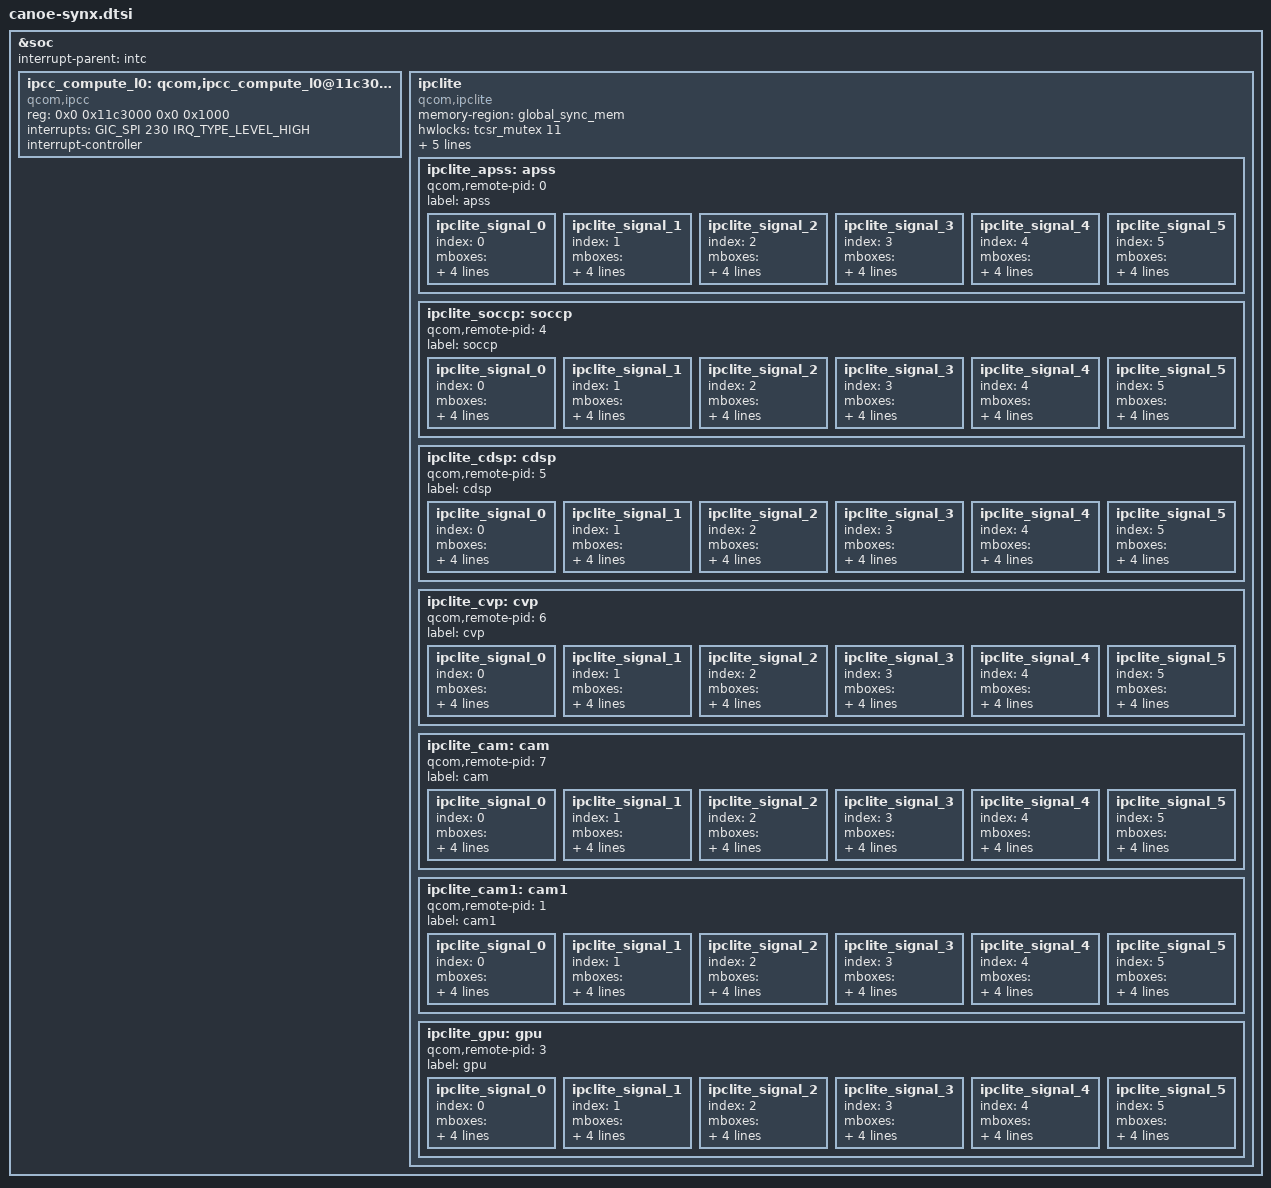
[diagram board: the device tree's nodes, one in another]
/* Copyright (c) Qualcomm Technologies, Inc. and/or its subsidiaries.
 * SPDX-License-Identifier: BSD-3-Clause
 */
#include <dt-bindings/ipclite-signals.h>

&soc {
	#address-cells = <2>;
	#size-cells = <2>;
	interrupt-parent = <&intc>;

	ipcc_compute_l0: qcom,ipcc_compute_l0@11c3000 {
		compatible = "qcom,ipcc";
		reg = <0x0 0x11c3000 0x0 0x1000>;
		interrupts = <GIC_SPI 230 IRQ_TYPE_LEVEL_HIGH>;
		interrupt-controller;
		#interrupt-cells = <3>;
		#mbox-cells = <2>;
	};
	ipclite {
		compatible = "qcom,ipclite";
		memory-region = <&global_sync_mem>;
		hwlocks = <&tcsr_mutex 11>;
		#address-cells = <2>;
		#size-cells = <2>;
		major_version = <1>;
		minor_version = <0>;
		feature_mask_low = <0x000F>;
		feature_mask_high = <0x0000>;
		global_par_custom_val=<40>;
		ranges;

		ipclite_apss: apss {
			qcom,remote-pid = <0>;
			label = "apss";

			ipclite_signal_0 {
				index = <0>;
				mboxes = <&ipcc_compute_l0 IPCC_COMPUTE_L0_APSS
					IPCC_COMPUTE_L0_SIGNAL_IPCLITE_MSG>;
					interrupt-parent = <&ipcc_compute_l0>;
				interrupts = <IPCC_COMPUTE_L0_APSS
					IPCC_COMPUTE_L0_SIGNAL_IPCLITE_MSG
					IRQ_TYPE_EDGE_RISING>;
			};

			ipclite_signal_1 {
				index = <1>;
				mboxes = <&ipcc_compute_l0 IPCC_CLIENT_BROADCAST
					IPCC_COMPUTE_L0_SIGNAL_IPCLITE_MEM_INIT>;
				interrupt-parent = <&ipcc_compute_l0>;
				interrupts = <IPCC_CLIENT_BROADCAST
					IPCC_COMPUTE_L0_SIGNAL_IPCLITE_MEM_INIT
					IRQ_TYPE_EDGE_RISING>;
			};

			ipclite_signal_2 {
				index = <2>;
				mboxes = <&ipcc_compute_l0 IPCC_COMPUTE_L0_APSS
					IPCC_COMPUTE_L0_SIGNAL_IPCLITE_VERSION>;
				interrupt-parent = <&ipcc_compute_l0>;
				interrupts = <IPCC_COMPUTE_L0_APSS
					IPCC_COMPUTE_L0_SIGNAL_IPCLITE_VERSION
					IRQ_TYPE_EDGE_RISING>;
			};

			ipclite_signal_3 {
				index = <3>;
				mboxes = <&ipcc_compute_l0 IPCC_COMPUTE_L0_APSS
					IPCC_COMPUTE_L0_SIGNAL_IPCLITE_TEST>;
				interrupt-parent = <&ipcc_compute_l0>;
				interrupts = <IPCC_COMPUTE_L0_APSS
					IPCC_COMPUTE_L0_SIGNAL_IPCLITE_TEST
					IRQ_TYPE_EDGE_RISING>;
			};

			ipclite_signal_4 {
				index = <4>;
				mboxes = <&ipcc_compute_l0 IPCC_COMPUTE_L0_APSS
					IPCC_COMPUTE_L0_SIGNAL_IPCLITE_SSR>;
				interrupt-parent = <&ipcc_compute_l0>;
				interrupts = <IPCC_COMPUTE_L0_APSS
					IPCC_COMPUTE_L0_SIGNAL_IPCLITE_SSR
					IRQ_TYPE_EDGE_RISING>;
			};

			ipclite_signal_5 {
				index = <5>;
				mboxes = <&ipcc_compute_l0 IPCC_COMPUTE_L0_APSS
					IPCC_COMPUTE_L0_SIGNAL_IPCLITE_DEBUG>;
				interrupt-parent = <&ipcc_compute_l0>;
				interrupts = <IPCC_COMPUTE_L0_APSS
					IPCC_COMPUTE_L0_SIGNAL_IPCLITE_DEBUG
					IRQ_TYPE_EDGE_RISING>;
			};
		};

		ipclite_soccp: soccp {
			qcom,remote-pid = <4>;
			label = "soccp";

			ipclite_signal_0 {
				index = <0>;
				mboxes = <&ipcc_compute_l0 IPCC_COMPUTE_L0_SOCCP
					IPCC_COMPUTE_L0_SIGNAL_IPCLITE_MSG>;
				interrupt-parent = <&ipcc_compute_l0>;
				interrupts = <IPCC_COMPUTE_L0_SOCCP
					IPCC_COMPUTE_L0_SIGNAL_IPCLITE_MSG
					IRQ_TYPE_EDGE_RISING>;
			};

			ipclite_signal_1 {
				index = <1>;
				mboxes = <&ipcc_compute_l0 IPCC_COMPUTE_L0_SOCCP
					IPCC_COMPUTE_L0_SIGNAL_IPCLITE_MEM_INIT>;
				interrupt-parent = <&ipcc_compute_l0>;
				interrupts = <IPCC_COMPUTE_L0_SOCCP
					IPCC_COMPUTE_L0_SIGNAL_IPCLITE_MEM_INIT
					IRQ_TYPE_EDGE_RISING>;
			};

			ipclite_signal_2 {
				index = <2>;
				mboxes = <&ipcc_compute_l0 IPCC_COMPUTE_L0_SOCCP
					IPCC_COMPUTE_L0_SIGNAL_IPCLITE_VERSION>;
				interrupt-parent = <&ipcc_compute_l0>;
				interrupts = <IPCC_COMPUTE_L0_SOCCP
					IPCC_COMPUTE_L0_SIGNAL_IPCLITE_VERSION
					IRQ_TYPE_EDGE_RISING>;
			};

			ipclite_signal_3 {
				index = <3>;
				mboxes = <&ipcc_compute_l0 IPCC_COMPUTE_L0_SOCCP
					IPCC_COMPUTE_L0_SIGNAL_IPCLITE_TEST>;
				interrupt-parent = <&ipcc_compute_l0>;
				interrupts = <IPCC_COMPUTE_L0_SOCCP
					IPCC_COMPUTE_L0_SIGNAL_IPCLITE_TEST
					IRQ_TYPE_EDGE_RISING>;
			};

			ipclite_signal_4 {
				index = <4>;
				mboxes = <&ipcc_compute_l0 IPCC_COMPUTE_L0_SOCCP
					IPCC_COMPUTE_L0_SIGNAL_IPCLITE_SSR>;
				interrupt-parent = <&ipcc_compute_l0>;
				interrupts = <IPCC_COMPUTE_L0_SOCCP
					IPCC_COMPUTE_L0_SIGNAL_IPCLITE_SSR
					IRQ_TYPE_EDGE_RISING>;
			};

			ipclite_signal_5 {
				index = <5>;
				mboxes = <&ipcc_compute_l0 IPCC_COMPUTE_L0_SOCCP
					IPCC_COMPUTE_L0_SIGNAL_IPCLITE_DEBUG>;
				interrupt-parent = <&ipcc_compute_l0>;
				interrupts = <IPCC_COMPUTE_L0_SOCCP
					IPCC_COMPUTE_L0_SIGNAL_IPCLITE_DEBUG
					IRQ_TYPE_EDGE_RISING>;
			};
		};

		ipclite_cdsp: cdsp {
			qcom,remote-pid = <5>;
			label = "cdsp";

			ipclite_signal_0 {
				index = <0>;
				mboxes = <&ipcc_compute_l0 IPCC_COMPUTE_L0_CDSP
					IPCC_COMPUTE_L0_SIGNAL_IPCLITE_MSG>;
				interrupt-parent = <&ipcc_compute_l0>;
				interrupts = <IPCC_COMPUTE_L0_CDSP
					IPCC_COMPUTE_L0_SIGNAL_IPCLITE_MSG
					IRQ_TYPE_EDGE_RISING>;
			};

			ipclite_signal_1 {
				index = <1>;
				mboxes = <&ipcc_compute_l0 IPCC_COMPUTE_L0_CDSP
					IPCC_COMPUTE_L0_SIGNAL_IPCLITE_MEM_INIT>;
				interrupt-parent = <&ipcc_compute_l0>;
				interrupts = <IPCC_COMPUTE_L0_CDSP
					IPCC_COMPUTE_L0_SIGNAL_IPCLITE_MEM_INIT
					IRQ_TYPE_EDGE_RISING>;
			};

			ipclite_signal_2 {
				index = <2>;
				mboxes = <&ipcc_compute_l0 IPCC_COMPUTE_L0_CDSP
					IPCC_COMPUTE_L0_SIGNAL_IPCLITE_VERSION>;
				interrupt-parent = <&ipcc_compute_l0>;
				interrupts = <IPCC_COMPUTE_L0_CDSP
					IPCC_COMPUTE_L0_SIGNAL_IPCLITE_VERSION
					IRQ_TYPE_EDGE_RISING>;
			};

			ipclite_signal_3 {
				index = <3>;
				mboxes = <&ipcc_compute_l0 IPCC_COMPUTE_L0_CDSP
					IPCC_COMPUTE_L0_SIGNAL_IPCLITE_TEST>;
				interrupt-parent = <&ipcc_compute_l0>;
				interrupts = <IPCC_COMPUTE_L0_CDSP
					IPCC_COMPUTE_L0_SIGNAL_IPCLITE_TEST
					IRQ_TYPE_EDGE_RISING>;
			};

			ipclite_signal_4 {
				index = <4>;
				mboxes = <&ipcc_compute_l0 IPCC_COMPUTE_L0_CDSP
					IPCC_COMPUTE_L0_SIGNAL_IPCLITE_SSR>;
				interrupt-parent = <&ipcc_compute_l0>;
				interrupts = <IPCC_COMPUTE_L0_CDSP
					IPCC_COMPUTE_L0_SIGNAL_IPCLITE_SSR
					IRQ_TYPE_EDGE_RISING>;
			};

			ipclite_signal_5 {
				index = <5>;
				mboxes = <&ipcc_compute_l0 IPCC_COMPUTE_L0_CDSP
					IPCC_COMPUTE_L0_SIGNAL_IPCLITE_DEBUG>;
				interrupt-parent = <&ipcc_compute_l0>;
				interrupts = <IPCC_COMPUTE_L0_CDSP
					IPCC_COMPUTE_L0_SIGNAL_IPCLITE_DEBUG
					IRQ_TYPE_EDGE_RISING>;
			};
		};

		ipclite_cvp: cvp {
			qcom,remote-pid = <6>;
			label = "cvp";

			ipclite_signal_0 {
				index = <0>;
				mboxes = <&ipcc_compute_l0 IPCC_COMPUTE_L0_CVP
					IPCC_COMPUTE_L0_SIGNAL_IPCLITE_MSG>;
				interrupt-parent = <&ipcc_compute_l0>;
				interrupts = <IPCC_COMPUTE_L0_CVP
					IPCC_COMPUTE_L0_SIGNAL_IPCLITE_MSG
					IRQ_TYPE_EDGE_RISING>;
			};

			ipclite_signal_1 {
				index = <1>;
				mboxes = <&ipcc_compute_l0 IPCC_COMPUTE_L0_CVP
					IPCC_COMPUTE_L0_SIGNAL_IPCLITE_MEM_INIT>;
				interrupt-parent = <&ipcc_compute_l0>;
				interrupts = <IPCC_COMPUTE_L0_CVP
					IPCC_COMPUTE_L0_SIGNAL_IPCLITE_MEM_INIT
					IRQ_TYPE_EDGE_RISING>;
			};

			ipclite_signal_2 {
				index = <2>;
				mboxes = <&ipcc_compute_l0 IPCC_COMPUTE_L0_CVP
					IPCC_COMPUTE_L0_SIGNAL_IPCLITE_VERSION>;
				interrupt-parent = <&ipcc_compute_l0>;
				interrupts = <IPCC_COMPUTE_L0_CVP
					IPCC_COMPUTE_L0_SIGNAL_IPCLITE_VERSION
					IRQ_TYPE_EDGE_RISING>;
			};

			ipclite_signal_3 {
				index = <3>;
				mboxes = <&ipcc_compute_l0 IPCC_COMPUTE_L0_CVP
					IPCC_COMPUTE_L0_SIGNAL_IPCLITE_TEST>;
				interrupt-parent = <&ipcc_compute_l0>;
				interrupts = <IPCC_COMPUTE_L0_CVP
					IPCC_COMPUTE_L0_SIGNAL_IPCLITE_TEST
					IRQ_TYPE_EDGE_RISING>;
			};

			ipclite_signal_4 {
				index = <4>;
				mboxes = <&ipcc_compute_l0 IPCC_COMPUTE_L0_CVP
					IPCC_COMPUTE_L0_SIGNAL_IPCLITE_SSR>;
				interrupt-parent = <&ipcc_compute_l0>;
				interrupts = <IPCC_COMPUTE_L0_CVP
					IPCC_COMPUTE_L0_SIGNAL_IPCLITE_SSR
					IRQ_TYPE_EDGE_RISING>;
			};

			ipclite_signal_5 {
				index = <5>;
				mboxes = <&ipcc_compute_l0 IPCC_COMPUTE_L0_CVP
					IPCC_COMPUTE_L0_SIGNAL_IPCLITE_DEBUG>;
				interrupt-parent = <&ipcc_compute_l0>;
				interrupts = <IPCC_COMPUTE_L0_CVP
					IPCC_COMPUTE_L0_SIGNAL_IPCLITE_DEBUG
					IRQ_TYPE_EDGE_RISING>;
			};
		};

		ipclite_cam: cam {
			qcom,remote-pid = <7>;
			label = "cam";

			ipclite_signal_0 {
				index = <0>;
				mboxes = <&ipcc_compute_l0 IPCC_COMPUTE_L0_CAM
					IPCC_COMPUTE_L0_SIGNAL_IPCLITE_MSG>;
				interrupt-parent = <&ipcc_compute_l0>;
				interrupts = <IPCC_COMPUTE_L0_CAM
					IPCC_COMPUTE_L0_SIGNAL_IPCLITE_MSG
					IRQ_TYPE_EDGE_RISING>;
			};

			ipclite_signal_1 {
				index = <1>;
				mboxes = <&ipcc_compute_l0 IPCC_COMPUTE_L0_CAM
					IPCC_COMPUTE_L0_SIGNAL_IPCLITE_MEM_INIT>;
				interrupt-parent = <&ipcc_compute_l0>;
				interrupts = <IPCC_COMPUTE_L0_CAM
					IPCC_COMPUTE_L0_SIGNAL_IPCLITE_MEM_INIT
					IRQ_TYPE_EDGE_RISING>;
			};

			ipclite_signal_2 {
				index = <2>;
				mboxes = <&ipcc_compute_l0 IPCC_COMPUTE_L0_CAM
					IPCC_COMPUTE_L0_SIGNAL_IPCLITE_VERSION>;
				interrupt-parent = <&ipcc_compute_l0>;
				interrupts = <IPCC_COMPUTE_L0_CAM
					IPCC_COMPUTE_L0_SIGNAL_IPCLITE_VERSION
					IRQ_TYPE_EDGE_RISING>;
			};

			ipclite_signal_3 {
				index = <3>;
				mboxes = <&ipcc_compute_l0 IPCC_COMPUTE_L0_CAM
					IPCC_COMPUTE_L0_SIGNAL_IPCLITE_TEST>;
				interrupt-parent = <&ipcc_compute_l0>;
				interrupts = <IPCC_COMPUTE_L0_CAM
					IPCC_COMPUTE_L0_SIGNAL_IPCLITE_TEST
					IRQ_TYPE_EDGE_RISING>;
			};

			ipclite_signal_4 {
				index = <4>;
				mboxes = <&ipcc_compute_l0 IPCC_COMPUTE_L0_CAM
					IPCC_COMPUTE_L0_SIGNAL_IPCLITE_SSR>;
				interrupt-parent = <&ipcc_compute_l0>;
				interrupts = <IPCC_COMPUTE_L0_CAM
					IPCC_COMPUTE_L0_SIGNAL_IPCLITE_SSR
					IRQ_TYPE_EDGE_RISING>;
			};

			ipclite_signal_5 {
				index = <5>;
				mboxes = <&ipcc_compute_l0 IPCC_COMPUTE_L0_CAM
					IPCC_COMPUTE_L0_SIGNAL_IPCLITE_DEBUG>;
				interrupt-parent = <&ipcc_compute_l0>;
				interrupts = <IPCC_COMPUTE_L0_CAM
					IPCC_COMPUTE_L0_SIGNAL_IPCLITE_DEBUG
					IRQ_TYPE_EDGE_RISING>;
			};
		};

		ipclite_cam1: cam1 {
			qcom,remote-pid = <1>;
			label = "cam1";

			ipclite_signal_0 {
				index = <0>;
				mboxes = <&ipcc_compute_l0 IPCC_COMPUTE_L0_CAM1
					IPCC_COMPUTE_L0_SIGNAL_IPCLITE_MSG>;
				interrupt-parent = <&ipcc_compute_l0>;
				interrupts = <IPCC_COMPUTE_L0_CAM1
					IPCC_COMPUTE_L0_SIGNAL_IPCLITE_MSG
					IRQ_TYPE_EDGE_RISING>;
			};

			ipclite_signal_1 {
				index = <1>;
				mboxes = <&ipcc_compute_l0 IPCC_COMPUTE_L0_CAM1
					IPCC_COMPUTE_L0_SIGNAL_IPCLITE_MEM_INIT>;
				interrupt-parent = <&ipcc_compute_l0>;
				interrupts = <IPCC_COMPUTE_L0_CAM1
					IPCC_COMPUTE_L0_SIGNAL_IPCLITE_MEM_INIT
					IRQ_TYPE_EDGE_RISING>;
			};

			ipclite_signal_2 {
				index = <2>;
				mboxes = <&ipcc_compute_l0 IPCC_COMPUTE_L0_CAM1
					IPCC_COMPUTE_L0_SIGNAL_IPCLITE_VERSION>;
				interrupt-parent = <&ipcc_compute_l0>;
				interrupts = <IPCC_COMPUTE_L0_CAM1
					IPCC_COMPUTE_L0_SIGNAL_IPCLITE_VERSION
					IRQ_TYPE_EDGE_RISING>;
			};

			ipclite_signal_3 {
				index = <3>;
				mboxes = <&ipcc_compute_l0 IPCC_COMPUTE_L0_CAM1
					IPCC_COMPUTE_L0_SIGNAL_IPCLITE_TEST>;
				interrupt-parent = <&ipcc_compute_l0>;
				interrupts = <IPCC_COMPUTE_L0_CAM1
					IPCC_COMPUTE_L0_SIGNAL_IPCLITE_TEST
					IRQ_TYPE_EDGE_RISING>;
			};

			ipclite_signal_4 {
				index = <4>;
				mboxes = <&ipcc_compute_l0 IPCC_COMPUTE_L0_CAM1
					IPCC_COMPUTE_L0_SIGNAL_IPCLITE_SSR>;
				interrupt-parent = <&ipcc_compute_l0>;
				interrupts = <IPCC_COMPUTE_L0_CAM1
					IPCC_COMPUTE_L0_SIGNAL_IPCLITE_SSR
					IRQ_TYPE_EDGE_RISING>;
			};

			ipclite_signal_5 {
				index = <5>;
				mboxes = <&ipcc_compute_l0 IPCC_COMPUTE_L0_CAM1
					IPCC_COMPUTE_L0_SIGNAL_IPCLITE_DEBUG>;
				interrupt-parent = <&ipcc_compute_l0>;
				interrupts = <IPCC_COMPUTE_L0_CAM1
					IPCC_COMPUTE_L0_SIGNAL_IPCLITE_DEBUG
					IRQ_TYPE_EDGE_RISING>;
			};
		};

		ipclite_gpu: gpu {
			qcom,remote-pid = <3>;
			label = "gpu";

			ipclite_signal_0 {
				index = <0>;
				mboxes = <&ipcc_compute_l0 IPCC_COMPUTE_L0_GPU
					IPCC_COMPUTE_L0_SIGNAL_IPCLITE_MSG>;
				interrupt-parent = <&ipcc_compute_l0>;
				interrupts = <IPCC_COMPUTE_L0_GPU
					IPCC_COMPUTE_L0_SIGNAL_IPCLITE_MSG
					IRQ_TYPE_EDGE_RISING>;
			};

			ipclite_signal_1 {
				index = <1>;
				mboxes = <&ipcc_compute_l0 IPCC_COMPUTE_L0_GPU
					IPCC_COMPUTE_L0_SIGNAL_IPCLITE_MEM_INIT>;
				interrupt-parent = <&ipcc_compute_l0>;
				interrupts = <IPCC_COMPUTE_L0_GPU
					IPCC_COMPUTE_L0_SIGNAL_IPCLITE_MEM_INIT
					IRQ_TYPE_EDGE_RISING>;
			};

			ipclite_signal_2 {
				index = <2>;
				mboxes = <&ipcc_compute_l0 IPCC_COMPUTE_L0_GPU
					IPCC_COMPUTE_L0_SIGNAL_IPCLITE_VERSION>;
				interrupt-parent = <&ipcc_compute_l0>;
				interrupts = <IPCC_COMPUTE_L0_GPU
					IPCC_COMPUTE_L0_SIGNAL_IPCLITE_VERSION
					IRQ_TYPE_EDGE_RISING>;
			};

			ipclite_signal_3 {
				index = <3>;
				mboxes = <&ipcc_compute_l0 IPCC_COMPUTE_L0_GPU
					IPCC_COMPUTE_L0_SIGNAL_IPCLITE_TEST>;
				interrupt-parent = <&ipcc_compute_l0>;
				interrupts = <IPCC_COMPUTE_L0_GPU
					IPCC_COMPUTE_L0_SIGNAL_IPCLITE_TEST
					IRQ_TYPE_EDGE_RISING>;
			};

			ipclite_signal_4 {
				index = <4>;
				mboxes = <&ipcc_compute_l0 IPCC_COMPUTE_L0_GPU
					IPCC_COMPUTE_L0_SIGNAL_IPCLITE_SSR>;
				interrupt-parent = <&ipcc_compute_l0>;
				interrupts = <IPCC_COMPUTE_L0_GPU
					IPCC_COMPUTE_L0_SIGNAL_IPCLITE_SSR
					IRQ_TYPE_EDGE_RISING>;
			};

			ipclite_signal_5 {
				index = <5>;
				mboxes = <&ipcc_compute_l0 IPCC_COMPUTE_L0_GPU
					IPCC_COMPUTE_L0_SIGNAL_IPCLITE_DEBUG>;
				interrupt-parent = <&ipcc_compute_l0>;
				interrupts = <IPCC_COMPUTE_L0_GPU
					IPCC_COMPUTE_L0_SIGNAL_IPCLITE_DEBUG
					IRQ_TYPE_EDGE_RISING>;
			};
		};
	};

};
